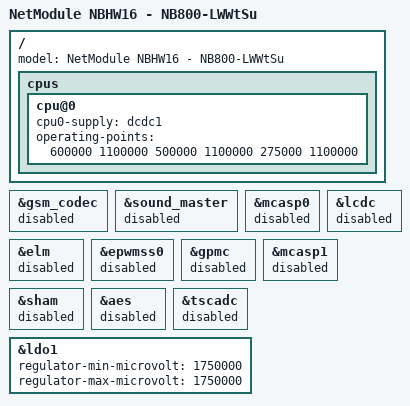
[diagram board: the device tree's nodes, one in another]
/*
 * Copyright (C) 2012 Texas Instruments Incorporated - http://www.ti.com/
 *
 * This program is free software; you can redistribute it and/or modify
 * it under the terms of the GNU General Public License version 2 as
 * published by the Free Software Foundation.
 */
#include "am335x-nbhw16-prod2.dts"

/ {
	model = "NetModule NBHW16 - NB800-LWWtSu";
	cpus {
		cpu@0 {
			cpu0-supply = <&dcdc1>;
			operating-points = <
				/* kHz    uV */
				600000  1100000
				500000  1100000
				275000  1100000
			>;
		};
	};
};

&gsm_codec {
    status = "disabled";
};

&sound_master {
    status = "disabled";
};

&mcasp0 {
    status = "disabled";
};

// &usb {
//  status = "disabled";
// };
// 
// &usb_ctrl_mod {
//  status = "disabled";
// };
//&usb0_phy {
// status = "disabled";
//};
//
//&usb0 {
// status = "disabled";
//};
//&usb1 {
// status = "disabled";
//};

&lcdc {
 status = "disabled";
};

&elm {
 status = "disabled";
};

&epwmss0 {
 status = "disabled";
};

&gpmc {
 status = "disabled";
};


&mcasp1 {
 status = "disabled";
};

&sham {
 status = "disabled";
};

&aes {
 status = "disabled";
};

&tscadc {
 status = "disabled";
};

&ldo1 {
    regulator-min-microvolt = <1750000>;
    regulator-max-microvolt = <1750000>;
};
